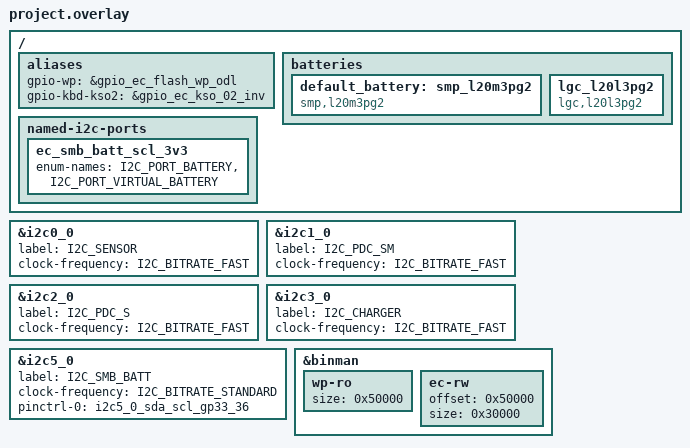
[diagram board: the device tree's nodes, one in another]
/* Copyright 2025 The ChromiumOS Authors
 * Use of this source code is governed by a BSD-style license that can be
 * found in the LICENSE file.
 */

#include "../common.dtsi"
#include "../power_signal.dtsi"
#include "../usba.dtsi"
//#include "../adc.dtsi"
#include "../host_interface.dtsi"
#include "../i2c.dtsi"
#include "../interrupts.dtsi"
#include "../gpio.dtsi"
//#include "../keyboard.dtsi"
#include "../usbc.dtsi"

/* board override */
/ {
	aliases {
		gpio-wp = &gpio_ec_flash_wp_odl;
		gpio-kbd-kso2 = &gpio_ec_kso_02_inv;
	};

	batteries {
		default_battery: smp_l20m3pg2 {
			compatible = "smp,l20m3pg2", "battery-smart";
		};
		lgc_l20l3pg2 {
			compatible = "lgc,l20l3pg2", "battery-smart";
		};
	};

	named-i2c-ports {
		ec_smb_batt_scl_3v3 {
			enum-names = "I2C_PORT_BATTERY", "I2C_PORT_VIRTUAL_BATTERY";
		};
	};
};

&i2c0_0 {
	label = "I2C_SENSOR";
	clock-frequency = <I2C_BITRATE_FAST>;
};

&i2c1_0 {
	label = "I2C_PDC_SM";
	clock-frequency = <I2C_BITRATE_FAST>;
};

&i2c2_0 {
	label = "I2C_PDC_S";
	clock-frequency = <I2C_BITRATE_FAST>;
};

&i2c3_0 {
	label = "I2C_CHARGER";
	clock-frequency = <I2C_BITRATE_FAST>;
};

&i2c5_0 {
	label = "I2C_SMB_BATT";
	clock-frequency = <I2C_BITRATE_STANDARD>;
	/* Upstream zephyr uses an irregular name here */
	pinctrl-0 = <&i2c5_0_sda_scl_gp33_36>;
};

&binman {
	wp-ro {
		size = <0x50000>;
	};
	ec-rw {
		offset = <0x50000>;
		size = <0x30000>;
	};
};
